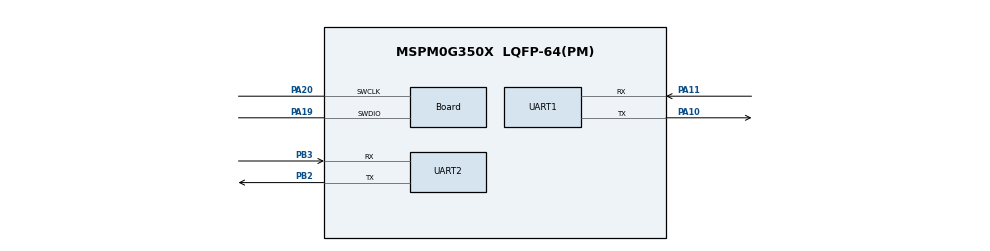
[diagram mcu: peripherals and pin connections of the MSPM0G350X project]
/**
 * @cliArgs --device "MSPM0G350X" --package "LQFP-64(PM)" --part "Default" --product "mspm0_sdk@2.00.01.00"
 * @versions {"tool":"1.20.0+3587"}
 */

/**
 * Import the modules used in this configuration.
 */
const Board         = scripting.addModule("/ti/driverlib/Board");
const GPIO          = scripting.addModule("/ti/driverlib/GPIO", {}, false);
const GPIO1         = GPIO.addInstance();
const GPIO2         = GPIO.addInstance();
const I2C           = scripting.addModule("/ti/driverlib/I2C", {}, false);
const I2C1          = I2C.addInstance();
const UART          = scripting.addModule("/ti/driverlib/UART", {}, false);
const UART1         = UART.addInstance();
const UART2         = UART.addInstance();
const ProjectConfig = scripting.addModule("/ti/project_config/ProjectConfig");

/**
 * Write custom configuration values to the imported modules.
 */
Board.peripheral.$assign          = "DEBUGSS";
Board.peripheral.swclkPin.$assign = "PA20";
Board.peripheral.swdioPin.$assign = "PA19";

GPIO1.$name                         = "GPIO_sda";
GPIO1.associatedPins[0].$name       = "PIN_0";
GPIO1.associatedPins[0].ioStructure = "OD";

GPIO2.$name                         = "GPIO_scl";
GPIO2.associatedPins[0].$name       = "PIN_1";
GPIO2.associatedPins[0].ioStructure = "OD";

I2C1.$name                             = "I2C_OLED";
I2C1.basicEnableController             = true;
I2C1.basicControllerStandardBusSpeed   = "Fast";
I2C1.sdaPinConfig.$name                = "ti_driverlib_gpio_GPIOPinGeneric0";
I2C1.sdaPinConfig.hideOutputInversion  = scripting.forceWrite(false);
I2C1.sdaPinConfig.onlyInternalResistor = scripting.forceWrite(false);
I2C1.sdaPinConfig.passedPeripheralType = scripting.forceWrite("Digital");
I2C1.sclPinConfig.$name                = "ti_driverlib_gpio_GPIOPinGeneric1";
I2C1.sclPinConfig.hideOutputInversion  = scripting.forceWrite(false);
I2C1.sclPinConfig.onlyInternalResistor = scripting.forceWrite(false);
I2C1.sclPinConfig.passedPeripheralType = scripting.forceWrite("Digital");

const SYSCTL              = scripting.addModule("/ti/driverlib/SYSCTL", {}, false);
SYSCTL.peripheral.$assign = "SYSCTL";

UART1.$name                    = "UART_0";
UART1.targetBaudRate           = 115200;
UART1.enabledInterrupts        = ["RX"];
UART1.peripheral.$assign       = "UART0";
UART1.peripheral.rxPin.$assign = "PA11";
UART1.peripheral.txPin.$assign = "PA10";
UART1.txPinConfig.$name        = "ti_driverlib_gpio_GPIOPinGeneric4";
UART1.rxPinConfig.$name        = "ti_driverlib_gpio_GPIOPinGeneric5";

UART2.$name                    = "UART_1";
UART2.targetBaudRate           = 115200;
UART2.enabledInterrupts        = ["RX"];
UART2.peripheral.rxPin.$assign = "PB3";
UART2.peripheral.txPin.$assign = "PB2";
UART2.txPinConfig.$name        = "ti_driverlib_gpio_GPIOPinGeneric2";
UART2.rxPinConfig.$name        = "ti_driverlib_gpio_GPIOPinGeneric3";

ProjectConfig.deviceSpin = "MSPM0G3507";
scripting.suppress("Migrating requires going through the Switch Board or Device menu in the Device View section\\.", ProjectConfig, "deviceSpin");

/**
 * Pinmux solution for unlocked pins/peripherals. This ensures that minor changes to the automatic solver in a future
 * version of the tool will not impact the pinmux you originally saw.  These lines can be completely deleted in order to
 * re-solve from scratch.
 */
GPIO1.associatedPins[0].pin.$suggestSolution = "PA1";
GPIO2.associatedPins[0].pin.$suggestSolution = "PA0";
I2C1.peripheral.$suggestSolution             = "I2C0";
I2C1.peripheral.sdaPin.$suggestSolution      = "PA28";
I2C1.peripheral.sclPin.$suggestSolution      = "PA31";
UART2.peripheral.$suggestSolution            = "UART3";
